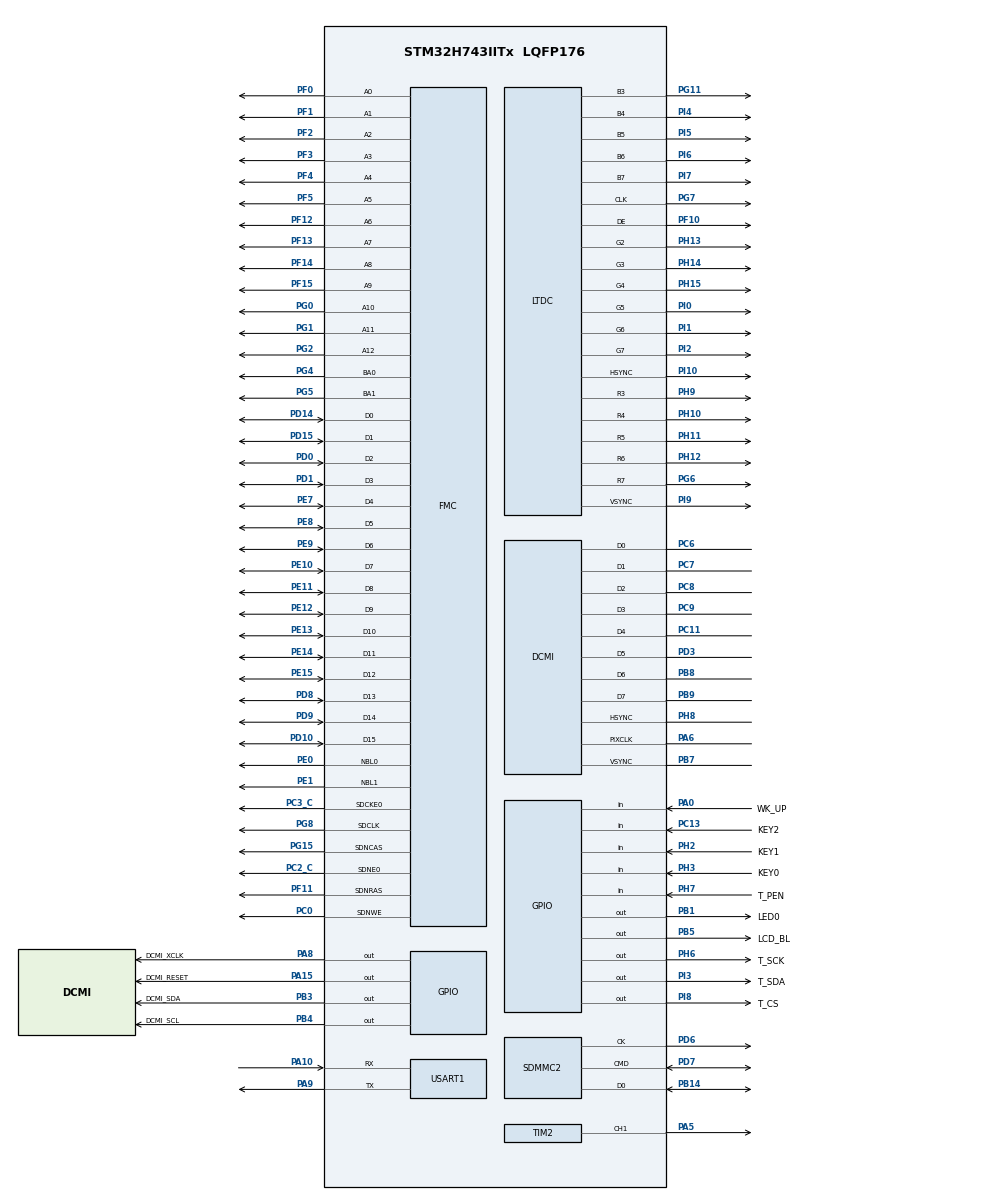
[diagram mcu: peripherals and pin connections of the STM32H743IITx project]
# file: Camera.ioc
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CORTEX_M7.AccessPermission_S-Cortex_Memory_Protection_Unit_Region1_Settings_S=MPU_REGION_FULL_ACCESS
CORTEX_M7.AccessPermission_S-Cortex_Memory_Protection_Unit_Region2_Settings_S=MPU_REGION_FULL_ACCESS
CORTEX_M7.AccessPermission_Spec=MPU_REGION_NO_ACCESS
CORTEX_M7.BaseAddress_S-Cortex_Memory_Protection_Unit_Region1_Settings_S=0xC0000000
CORTEX_M7.BaseAddress_S-Cortex_Memory_Protection_Unit_Region2_Settings_S=0x24000000
CORTEX_M7.BaseAddress_Spec=0
CORTEX_M7.CPU_DCache=Enabled
CORTEX_M7.CPU_ICache=Enabled
CORTEX_M7.DisableExec_S-Cortex_Memory_Protection_Unit_Region1_Settings_S=MPU_INSTRUCTION_ACCESS_DISABLE
CORTEX_M7.DisableExec_Spec=MPU_INSTRUCTION_ACCESS_DISABLE
CORTEX_M7.Enable_S-Cortex_Memory_Protection_Unit_Region1_Settings_S=MPU_REGION_ENABLE
CORTEX_M7.Enable_S-Cortex_Memory_Protection_Unit_Region2_Settings_S=MPU_REGION_ENABLE
CORTEX_M7.Enable_S-Cortex_Memory_Protection_Unit_Region3_Settings_S=__NULL
CORTEX_M7.Enable_Spec=MPU_REGION_ENABLE
CORTEX_M7.IsBufferable_S-Cortex_Memory_Protection_Unit_Region2_Settings_S=MPU_ACCESS_BUFFERABLE
CORTEX_M7.IsCacheable_S-Cortex_Memory_Protection_Unit_Region2_Settings_S=MPU_ACCESS_CACHEABLE
CORTEX_M7.IsShareable_Spec=MPU_ACCESS_NOT_SHAREABLE
CORTEX_M7.MPU_Control=MPU_PRIVILEGED_DEFAULT
CORTEX_M7.Size_S-Cortex_Memory_Protection_Unit_Region1_Settings_S=MPU_REGION_SIZE_32MB
CORTEX_M7.Size_S-Cortex_Memory_Protection_Unit_Region2_Settings_S=MPU_REGION_SIZE_512KB
CORTEX_M7.Size_Spec=MPU_REGION_SIZE_4GB
CORTEX_M7.TypeExtField_S-Cortex_Memory_Protection_Unit_Region1_Settings_S=MPU_TEX_LEVEL1
CORTEX_M7.TypeExtField_S-Cortex_Memory_Protection_Unit_Region2_Settings_S=MPU_TEX_LEVEL1
CORTEX_M7.default_mode_Activation=1
DCMI.HSPolarity=DCMI_HSPOLARITY_HIGH
DCMI.PCKPolarity=DCMI_PCKPOLARITY_RISING
DCMI.VSPolarity=DCMI_VSPOLARITY_HIGH
DMA2D.ColorMode=DMA2D_OUTPUT_RGB565
DMA2D.Mode=DMA2D_M2M
Dma.DCMI.0.Direction=DMA_PERIPH_TO_MEMORY
Dma.DCMI.0.EventEnable=DISABLE
Dma.DCMI.0.FIFOMode=DMA_FIFOMODE_DISABLE
Dma.DCMI.0.Instance=DMA1_Stream0
Dma.DCMI.0.MemDataAlignment=DMA_MDATAALIGN_WORD
Dma.DCMI.0.MemInc=DMA_MINC_ENABLE
Dma.DCMI.0.Mode=DMA_NORMAL
Dma.DCMI.0.PeriphDataAlignment=DMA_PDATAALIGN_WORD
Dma.DCMI.0.PeriphInc=DMA_PINC_DISABLE
Dma.DCMI.0.Polarity=HAL_DMAMUX_REQ_GEN_RISING
Dma.DCMI.0.Priority=DMA_PRIORITY_VERY_HIGH
Dma.DCMI.0.RequestNumber=1
Dma.DCMI.0.SignalID=NONE
Dma.DCMI.0.SyncEnable=DISABLE
Dma.DCMI.0.SyncPolarity=HAL_DMAMUX_SYNC_NO_EVENT
Dma.DCMI.0.SyncRequestNumber=1
Dma.DCMI.0.SyncSignalID=NONE
Dma.Request0=DCMI
FMC.CASLatency1=FMC_SDRAM_CAS_LATENCY_3
FMC.ColumnBitsNumber1=FMC_SDRAM_COLUMN_BITS_NUM_9
FMC.ExitSelfRefreshDelay1=7
FMC.LoadToActiveDelay1=2
FMC.RCDDelay1=2
FMC.RPDelay1=2
FMC.ReadBurst1=FMC_SDRAM_RBURST_ENABLE
FMC.ReadPipeDelay1=FMC_SDRAM_RPIPE_DELAY_1
FMC.RowCycleDelay1=7
FMC.SDClockPeriod1=FMC_SDRAM_CLOCK_PERIOD_2
FMC.SelfRefreshTime1=4
FMC.WriteRecoveryTime1=3
FREERTOS.MEMORY_ALLOCATION=0
FREERTOS.Tasks01=Initial_Task,1,2048,initial_task_routine,As weak,NULL,Dynamic,NULL,NULL;TouchSence_Task,0,2048,touch_sence_routine,As weak,NULL,Dynamic,NULL,NULL;Camera_Task,0,2048,camera_task_routine,As weak,NULL,Dynamic,NULL,NULL
FREERTOS.configCHECK_FOR_STACK_OVERFLOW=1
FREERTOS.configENABLE_FPU=1
FREERTOS.configGENERATE_RUN_TIME_STATS=1
FREERTOS.configLIBRARY_LOWEST_INTERRUPT_PRIORITY=15
FREERTOS.configLIBRARY_MAX_SYSCALL_INTERRUPT_PRIORITY=6
FREERTOS.configMAX_PRIORITIES=15
FREERTOS.configMINIMAL_STACK_SIZE=512
FREERTOS.configQUEUE_REGISTRY_SIZE=32
FREERTOS.configTIMER_TASK_PRIORITY=6
FREERTOS.configTIMER_TASK_STACK_DEPTH=2048
FREERTOS.configTOTAL_HEAP_SIZE=131072
FREERTOS.configUSE_COUNTING_SEMAPHORES=1
FREERTOS.configUSE_CO_ROUTINES=1
FREERTOS.configUSE_IDLE_HOOK=1
FREERTOS.configUSE_MALLOC_FAILED_HOOK=1
FREERTOS.configUSE_NEWLIB_REENTRANT=1
FREERTOS.configUSE_RECURSIVE_MUTEXES=1
FREERTOS.configUSE_STATS_FORMATTING_FUNCTIONS=1
FREERTOS.configUSE_TICK_HOOK=1
FREERTOS.configUSE_TIMERS=1
FREERTOS.configUSE_TRACE_FACILITY=1
JPEG.JPEG_RGB_FORMAT=JPEG_RGB565
JPEG.JPEG_SWAP_RG=1
LTDC.ActiveH=272
LTDC.ActiveW=480
LTDC.Alpha0_L0=0
LTDC.Alpha_L0=255
LTDC.Alpha_L1=255
LTDC.BlendingFactor1_L0=LTDC_BLENDING_FACTOR1_CA
LTDC.BlendingFactor1_L1=LTDC_BLENDING_FACTOR1_PAxCA
LTDC.BlendingFactor2_L0=LTDC_BLENDING_FACTOR2_CA
LTDC.BlendingFactor2_L1=LTDC_BLENDING_FACTOR2_PAxCA
LTDC.Blue=255
LTDC.Blue_L0=0
LTDC.FBStartAdress_L0=0
LTDC.FBStartAdress_L1=SDRAM_LAYER1
LTDC.Green=255
LTDC.Green_L0=0
LTDC.HBP=40
LTDC.HFP=5
LTDC.HSync=1
LTDC.ImageHeight_L0=272
LTDC.ImageHeight_L1=272
LTDC.ImageWidth_L0=480
LTDC.Layers=0
LTDC.PCPolarity=LTDC_PCPOLARITY_IPC
LTDC.PixelFormat_L0=LTDC_PIXEL_FORMAT_RGB565
LTDC.Red=255
LTDC.Red_L0=0
LTDC.VBP=8
LTDC.VFP=8
LTDC.VSync=1
LTDC.WindowX1_L0=480
LTDC.WindowX1_L1=480
LTDC.WindowY1_L0=272
LTDC.WindowY1_L1=272
Mcu.Family=STM32H7
Mcu.Name=STM32H743IITx
Mcu.Package=LQFP176
Mdma.MDMA_Channel0.JPEG_INFIFO_TH.0.BlockCount=0
Mdma.MDMA_Channel0.JPEG_INFIFO_TH.0.BlockDataLength=0
Mdma.MDMA_Channel0.JPEG_INFIFO_TH.0.BufferTransferLength=32
Mdma.MDMA_Channel0.JPEG_INFIFO_TH.0.CircularMode=MDMA_LINEAR_LIST
Mdma.MDMA_Channel0.JPEG_INFIFO_TH.0.DataAlignment=MDMA_DATAALIGN_PACKENABLE
Mdma.MDMA_Channel0.JPEG_INFIFO_TH.0.DestBlockAddressOffset=0
Mdma.MDMA_Channel0.JPEG_INFIFO_TH.0.DestBurst=MDMA_DEST_BURST_16BEATS
Mdma.MDMA_Channel0.JPEG_INFIFO_TH.0.DestDataSize=MDMA_DEST_DATASIZE_WORD
Mdma.MDMA_Channel0.JPEG_INFIFO_TH.0.DestinationInc=MDMA_DEST_INC_DISABLE
Mdma.MDMA_Channel0.JPEG_INFIFO_TH.0.DstAddress=0
Mdma.MDMA_Channel0.JPEG_INFIFO_TH.0.Endianness=MDMA_LITTLE_ENDIANNESS_PRESERVE
Mdma.MDMA_Channel0.JPEG_INFIFO_TH.0.Instance=MDMA_Channel0
Mdma.MDMA_Channel0.JPEG_INFIFO_TH.0.MaskAddress=0
Mdma.MDMA_Channel0.JPEG_INFIFO_TH.0.MaskData=0
Mdma.MDMA_Channel0.JPEG_INFIFO_TH.0.Priority=MDMA_PRIORITY_LOW
Mdma.MDMA_Channel0.JPEG_INFIFO_TH.0.Rank=First
Mdma.MDMA_Channel0.JPEG_INFIFO_TH.0.SourceBlockAddressOffset=0
Mdma.MDMA_Channel0.JPEG_INFIFO_TH.0.SourceBurst=MDMA_SOURCE_BURST_32BEATS
Mdma.MDMA_Channel0.JPEG_INFIFO_TH.0.SourceDataSize=MDMA_SRC_DATASIZE_BYTE
Mdma.MDMA_Channel0.JPEG_INFIFO_TH.0.SourceInc=MDMA_SRC_INC_BYTE
Mdma.MDMA_Channel0.JPEG_INFIFO_TH.0.SrcAddress=0
Mdma.MDMA_Channel0.JPEG_INFIFO_TH.0.TransferTriggerMode=MDMA_BUFFER_TRANSFER
Mdma.MDMA_Channel0.Request0=JPEG_INFIFO_TH
Mdma.MDMA_Channel0.RequestsNb=1
Mdma.MDMA_Channel1.JPEG_OUTFIFO_TH.0.BlockCount=0
Mdma.MDMA_Channel1.JPEG_OUTFIFO_TH.0.BlockDataLength=0
Mdma.MDMA_Channel1.JPEG_OUTFIFO_TH.0.BufferTransferLength=32
Mdma.MDMA_Channel1.JPEG_OUTFIFO_TH.0.CircularMode=MDMA_LINEAR_LIST
Mdma.MDMA_Channel1.JPEG_OUTFIFO_TH.0.DataAlignment=MDMA_DATAALIGN_PACKENABLE
Mdma.MDMA_Channel1.JPEG_OUTFIFO_TH.0.DestBlockAddressOffset=0
Mdma.MDMA_Channel1.JPEG_OUTFIFO_TH.0.DestBurst=MDMA_DEST_BURST_32BEATS
Mdma.MDMA_Channel1.JPEG_OUTFIFO_TH.0.DestDataSize=MDMA_DEST_DATASIZE_BYTE
Mdma.MDMA_Channel1.JPEG_OUTFIFO_TH.0.DestinationInc=MDMA_DEST_INC_BYTE
Mdma.MDMA_Channel1.JPEG_OUTFIFO_TH.0.DstAddress=0
Mdma.MDMA_Channel1.JPEG_OUTFIFO_TH.0.Endianness=MDMA_LITTLE_ENDIANNESS_PRESERVE
Mdma.MDMA_Channel1.JPEG_OUTFIFO_TH.0.Instance=MDMA_Channel1
Mdma.MDMA_Channel1.JPEG_OUTFIFO_TH.0.MaskAddress=0
Mdma.MDMA_Channel1.JPEG_OUTFIFO_TH.0.MaskData=0
Mdma.MDMA_Channel1.JPEG_OUTFIFO_TH.0.Priority=MDMA_PRIORITY_LOW
Mdma.MDMA_Channel1.JPEG_OUTFIFO_TH.0.Rank=First
Mdma.MDMA_Channel1.JPEG_OUTFIFO_TH.0.SourceBlockAddressOffset=0
Mdma.MDMA_Channel1.JPEG_OUTFIFO_TH.0.SourceBurst=MDMA_SOURCE_BURST_16BEATS
Mdma.MDMA_Channel1.JPEG_OUTFIFO_TH.0.SourceDataSize=MDMA_SRC_DATASIZE_WORD
Mdma.MDMA_Channel1.JPEG_OUTFIFO_TH.0.SourceInc=MDMA_SRC_INC_DISABLE
Mdma.MDMA_Channel1.JPEG_OUTFIFO_TH.0.SrcAddress=0
Mdma.MDMA_Channel1.JPEG_OUTFIFO_TH.0.TransferTriggerMode=MDMA_BUFFER_TRANSFER
Mdma.MDMA_Channel1.Request0=JPEG_OUTFIFO_TH
Mdma.MDMA_Channel1.RequestsNb=1
Mdma.RequestSet0=MDMA_Channel0
Mdma.RequestSet1=MDMA_Channel1
Mdma.RequestSetsNb=2
NVIC.DMA1_Stream0_IRQn=true\:6\:0\:false\:false\:true\:true\:false\:true\:true
NVIC.DMA2D_IRQn=true\:6\:0\:false\:false\:true\:true\:true\:true\:true
NVIC.FMC_IRQn=true\:6\:0\:false\:false\:true\:true\:true\:true\:true
NVIC.JPEG_IRQn=true\:6\:0\:false\:false\:true\:true\:true\:true\:true
NVIC.LTDC_IRQn=true\:6\:0\:false\:false\:true\:true\:true\:true\:true
NVIC.MDMA_IRQn=true\:6\:0\:false\:false\:true\:true\:false\:true\:true
NVIC.PriorityGroup=NVIC_PRIORITYGROUP_4
NVIC.TIM3_IRQn=true\:5\:0\:true\:false\:true\:false\:true\:true\:true
NVIC.TIM7_IRQn=true\:15\:0\:true\:false\:true\:false\:false\:true\:true
NVIC.TimeBase=TIM7_IRQn
NVIC.TimeBaseIP=TIM7
PA0.GPIO_Label=WK_UP
PA0.GPIO_PuPd=GPIO_PULLDOWN
PA0.Signal=GPIO_Input
PA10.GPIO_Speed=GPIO_SPEED_FREQ_VERY_HIGH
PA10.Mode=Asynchronous
PA10.Signal=USART1_RX
PA13\ (JTMS/SWDIO).Mode=Serial_Wire
PA13\ (JTMS/SWDIO).Signal=DEBUG_JTMS-SWDIO
PA14\ (JTCK/SWCLK).Mode=Serial_Wire
PA14\ (JTCK/SWCLK).Signal=DEBUG_JTCK-SWCLK
PA15\ (JTDI).GPIO_Label=DCMI_RESET
PA15\ (JTDI).GPIO_Speed=GPIO_SPEED_FREQ_VERY_HIGH
PA15\ (JTDI).Signal=GPIO_Output
PA5.GPIO_Speed=GPIO_SPEED_FREQ_VERY_HIGH
PA5.Signal=S_TIM2_CH1_ETR
PA6.GPIO_Speed=GPIO_SPEED_FREQ_VERY_HIGH
PA6.Mode=Slave_8_bits_External_Synchro
PA6.Signal=DCMI_PIXCLK
PA8.GPIO_Label=DCMI_XCLK
PA8.GPIO_Speed=GPIO_SPEED_FREQ_VERY_HIGH
PA8.Signal=GPIO_Output
PA9.GPIO_Speed=GPIO_SPEED_FREQ_VERY_HIGH
PA9.Mode=Asynchronous
PA9.Signal=USART1_TX
PB1.GPIO_Label=LED0
PB1.GPIO_Speed=GPIO_SPEED_FREQ_VERY_HIGH
PB1.PinState=GPIO_PIN_SET
PB1.Signal=GPIO_Output
PB14.Mode=SD_1_bit
PB14.Signal=SDMMC2_D0
PB3\ (JTDO/TRACESWO).GPIO_Label=DCMI_SDA
PB3\ (JTDO/TRACESWO).GPIO_Speed=GPIO_SPEED_FREQ_VERY_HIGH
PB3\ (JTDO/TRACESWO).PinState=GPIO_PIN_RESET
PB3\ (JTDO/TRACESWO).Signal=GPIO_Output
PB4\ (NJTRST).GPIO_Label=DCMI_SCL
PB4\ (NJTRST).GPIO_Speed=GPIO_SPEED_FREQ_VERY_HIGH
PB4\ (NJTRST).Signal=GPIO_Output
PB5.GPIO_Label=LCD_BL
PB5.GPIO_Speed=GPIO_SPEED_FREQ_VERY_HIGH
PB5.PinState=GPIO_PIN_SET
PB5.Signal=GPIO_Output
PB7.GPIO_Speed=GPIO_SPEED_FREQ_VERY_HIGH
PB7.Mode=Slave_8_bits_External_Synchro
PB7.Signal=DCMI_VSYNC
PB8.GPIO_Speed=GPIO_SPEED_FREQ_VERY_HIGH
PB8.Mode=Slave_8_bits_External_Synchro
PB8.Signal=DCMI_D6
PB9.GPIO_Speed=GPIO_SPEED_FREQ_VERY_HIGH
PB9.Mode=Slave_8_bits_External_Synchro
PB9.Signal=DCMI_D7
PC0.Signal=FMC_SDNWE
PC10.Signal=SDMMC1_D2
PC11.Signal=SharedStack_PC11
PC11.Stacked=true
PC12.Signal=SDMMC1_CK
PC13.GPIO_Label=KEY2
PC13.GPIO_Mode=GPIO_MODE_INPUT
PC13.GPIO_PuPd=GPIO_PULLUP
PC13.Signal=GPIO_Input
PC14-OSC32_IN\ (OSC32_IN).Mode=LSE-External-Oscillator
PC14-OSC32_IN\ (OSC32_IN).Signal=RCC_OSC32_IN
PC15-OSC32_OUT\ (OSC32_OUT).Mode=LSE-External-Oscillator
PC15-OSC32_OUT\ (OSC32_OUT).Signal=RCC_OSC32_OUT
PC2_C.Mode=SdramChipSelect1_1
PC2_C.Signal=FMC_SDNE0
PC3_C.Mode=SdramChipSelect1_1
PC3_C.Signal=FMC_SDCKE0
PC6.GPIO_Speed=GPIO_SPEED_FREQ_VERY_HIGH
PC6.Mode=Slave_8_bits_External_Synchro
PC6.Signal=DCMI_D0
PC7.GPIO_Speed=GPIO_SPEED_FREQ_VERY_HIGH
PC7.Mode=Slave_8_bits_External_Synchro
PC7.Signal=DCMI_D1
PC8.Mode=Slave_8_bits_External_Synchro
PC8.Signal=DCMI_D2
PC8.Stacked=true
PC9.Mode=Slave_8_bits_External_Synchro
PC9.Signal=DCMI_D3
PC9.Stacked=true
PD0.Signal=FMC_D2_DA2
PD1.Signal=FMC_D3_DA3
PD10.Signal=FMC_D15_DA15
PD14.Signal=FMC_D0_DA0
PD15.Signal=FMC_D1_DA1
PD2.Signal=SDMMC1_CMD
PD3.GPIO_Speed=GPIO_SPEED_FREQ_VERY_HIGH
PD3.Mode=Slave_8_bits_External_Synchro
PD3.Signal=DCMI_D5
PD6.Mode=SD_1_bit
PD6.Signal=SDMMC2_CK
PD7.Mode=SD_1_bit
PD7.Signal=SDMMC2_CMD
PD8.Signal=FMC_D13_DA13
PD9.Signal=FMC_D14_DA14
PE0.Signal=FMC_NBL0
PE1.Signal=FMC_NBL1
PE10.Signal=FMC_D7_DA7
PE11.Signal=FMC_D8_DA8
PE12.Signal=FMC_D9_DA9
PE13.Signal=FMC_D10_DA10
PE14.Signal=FMC_D11_DA11
PE15.Signal=FMC_D12_DA12
PE7.Signal=FMC_D4_DA4
PE8.Signal=FMC_D5_DA5
PE9.Signal=FMC_D6_DA6
PF0.Signal=FMC_A0
PF1.Signal=FMC_A1
PF10.GPIO_Speed=GPIO_SPEED_FREQ_VERY_HIGH
PF10.Mode=RGB565
PF10.Signal=LTDC_DE
PF11.Signal=FMC_SDNRAS
PF12.Signal=FMC_A6
PF13.Signal=FMC_A7
PF14.Signal=FMC_A8
PF15.Signal=FMC_A9
PF2.Signal=FMC_A2
PF3.Signal=FMC_A3
PF4.Signal=FMC_A4
PF5.Signal=FMC_A5
PG0.Signal=FMC_A10
PG1.Signal=FMC_A11
PG11.GPIO_Speed=GPIO_SPEED_FREQ_VERY_HIGH
PG11.Mode=RGB565
PG11.Signal=LTDC_B3
PG15.Signal=FMC_SDNCAS
PG2.Signal=FMC_A12
PG4.Signal=FMC_A14_BA0
PG5.Signal=FMC_A15_BA1
PG6.GPIO_Speed=GPIO_SPEED_FREQ_VERY_HIGH
PG6.Mode=RGB565
PG6.Signal=LTDC_R7
PG7.GPIO_Speed=GPIO_SPEED_FREQ_VERY_HIGH
PG7.Mode=RGB565
PG7.Signal=LTDC_CLK
PG8.Signal=FMC_SDCLK
PH0-OSC_IN\ (PH0).Mode=HSE-External-Oscillator
PH0-OSC_IN\ (PH0).Signal=RCC_OSC_IN
PH1-OSC_OUT\ (PH1).Mode=HSE-External-Oscillator
PH1-OSC_OUT\ (PH1).Signal=RCC_OSC_OUT
PH10.GPIO_Speed=GPIO_SPEED_FREQ_VERY_HIGH
PH10.Mode=RGB565
PH10.Signal=LTDC_R4
PH11.GPIO_Speed=GPIO_SPEED_FREQ_VERY_HIGH
PH11.Mode=RGB565
PH11.Signal=LTDC_R5
PH12.GPIO_Speed=GPIO_SPEED_FREQ_VERY_HIGH
PH12.Mode=RGB565
PH12.Signal=LTDC_R6
PH13.GPIO_Speed=GPIO_SPEED_FREQ_VERY_HIGH
PH13.Mode=RGB565
PH13.Signal=LTDC_G2
PH14.GPIO_Speed=GPIO_SPEED_FREQ_VERY_HIGH
PH14.Mode=RGB565
PH14.Signal=LTDC_G3
PH15.GPIO_Speed=GPIO_SPEED_FREQ_VERY_HIGH
PH15.Mode=RGB565
PH15.Signal=LTDC_G4
PH2.GPIO_Label=KEY1
PH2.GPIO_Mode=GPIO_MODE_INPUT
PH2.GPIO_PuPd=GPIO_PULLUP
PH2.Signal=GPIO_Input
PH3.GPIO_Label=KEY0
PH3.GPIO_Mode=GPIO_MODE_INPUT
PH3.GPIO_PuPd=GPIO_PULLUP
PH3.Signal=GPIO_Input
PH6.GPIO_Label=T_SCK
PH6.GPIO_ModeDefaultOutputPP=GPIO_MODE_OUTPUT_OD
PH6.GPIO_PuPd=GPIO_PULLUP
PH6.GPIO_Speed=GPIO_SPEED_FREQ_VERY_HIGH
PH6.PinState=GPIO_PIN_SET
PH6.Signal=GPIO_Output
PH7.GPIO_Label=T_PEN
PH7.GPIO_PuPd=GPIO_PULLUP
PH7.Signal=GPIO_Input
PH8.GPIO_Speed=GPIO_SPEED_FREQ_VERY_HIGH
PH8.Mode=Slave_8_bits_External_Synchro
PH8.Signal=DCMI_HSYNC
PH9.GPIO_Speed=GPIO_SPEED_FREQ_VERY_HIGH
PH9.Mode=RGB565
PH9.Signal=LTDC_R3
PI0.GPIO_Speed=GPIO_SPEED_FREQ_VERY_HIGH
PI0.Mode=RGB565
PI0.Signal=LTDC_G5
PI1.GPIO_Speed=GPIO_SPEED_FREQ_VERY_HIGH
PI1.Mode=RGB565
PI1.Signal=LTDC_G6
PI10.GPIO_Speed=GPIO_SPEED_FREQ_VERY_HIGH
PI10.Mode=RGB565
PI10.Signal=LTDC_HSYNC
PI2.GPIO_Speed=GPIO_SPEED_FREQ_VERY_HIGH
PI2.Mode=RGB565
PI2.Signal=LTDC_G7
PI3.GPIO_Label=T_SDA
PI3.GPIO_ModeDefaultOutputPP=GPIO_MODE_OUTPUT_OD
PI3.GPIO_PuPd=GPIO_PULLUP
PI3.GPIO_Speed=GPIO_SPEED_FREQ_VERY_HIGH
PI3.PinState=GPIO_PIN_SET
PI3.Signal=GPIO_Output
PI4.GPIO_Speed=GPIO_SPEED_FREQ_VERY_HIGH
PI4.Mode=RGB565
PI4.Signal=LTDC_B4
PI5.GPIO_Speed=GPIO_SPEED_FREQ_VERY_HIGH
PI5.Mode=RGB565
PI5.Signal=LTDC_B5
PI6.GPIO_Speed=GPIO_SPEED_FREQ_VERY_HIGH
PI6.Mode=RGB565
PI6.Signal=LTDC_B6
PI7.GPIO_Speed=GPIO_SPEED_FREQ_VERY_HIGH
PI7.Mode=RGB565
PI7.Signal=LTDC_B7
PI8.GPIO_Label=T_CS
PI8.GPIO_PuPd=GPIO_NOPULL
PI8.GPIO_Speed=GPIO_SPEED_FREQ_LOW
PI8.PinState=GPIO_PIN_RESET
PI8.Signal=GPIO_Output
PI9.GPIO_Speed=GPIO_SPEED_FREQ_VERY_HIGH
PI9.Mode=RGB565
PI9.Signal=LTDC_VSYNC
ProjectManager.HeapSize=0x1000
ProjectManager.StackSize=0x1000
ProjectManager.TargetToolchain=CMake
RCC.ADCFreq_Value=100000000
RCC.APB1Freq_Value=120000000
RCC.APB2Freq_Value=120000000
RCC.APB3Freq_Value=120000000
RCC.APB4Freq_Value=120000000
RCC.CortexFreq_Value=480000000
RCC.D1PPRE=RCC_APB3_DIV2
RCC.D2PPRE1=RCC_APB1_DIV2
RCC.D2PPRE2=RCC_APB2_DIV2
RCC.D3PPRE=RCC_APB4_DIV2
RCC.DIVM1=5
RCC.DIVM2=5
RCC.DIVM3=5
RCC.DIVN1=192
RCC.DIVN2=40
RCC.DIVN3=36
RCC.DIVQ1=3
RCC.DIVR2=1
RCC.DIVR3=20
RCC.FMCCLockSelection=RCC_FMCCLKSOURCE_PLL2
RCC.HCLKFreq_Value=240000000
RCC.HPRE=RCC_HCLK_DIV2
RCC.PLL2FRACN=0
RCC.PLLSourceVirtual=RCC_PLLSOURCE_HSE
RCC.RTCClockSelection=RCC_RTCCLKSOURCE_LSE
RCC.SDMMC1CLockSelection=RCC_SDMMCCLKSOURCE_PLL2
RCC.SYSCLKFreq_VALUE=480000000
RCC.SYSCLKSource=RCC_SYSCLKSOURCE_PLLCLK
RCC.Tim1Mul=2
RCC.USBFreq_Value=320000000
RTC.Date=8
RTC.Hours=0
RTC.Minutes=0
RTC.Month=RTC_MONTH_NOVEMBER
RTC.Seconds=0
RTC.WeekDay=RTC_WEEKDAY_SATURDAY
RTC.Year=23
SDMMC2.ClockDiv=4
SH.FMC_A0.0=FMC_A0,13b-sda1
SH.FMC_A1.0=FMC_A1,13b-sda1
SH.FMC_A10.0=FMC_A10,13b-sda1
SH.FMC_A11.0=FMC_A11,13b-sda1
SH.FMC_A12.0=FMC_A12,13b-sda1
SH.FMC_A14_BA0.0=FMC_BA0,FourSdramBanks1
SH.FMC_A15_BA1.0=FMC_BA1,FourSdramBanks1
SH.FMC_A2.0=FMC_A2,13b-sda1
SH.FMC_A3.0=FMC_A3,13b-sda1
SH.FMC_A4.0=FMC_A4,13b-sda1
SH.FMC_A5.0=FMC_A5,13b-sda1
SH.FMC_A6.0=FMC_A6,13b-sda1
SH.FMC_A7.0=FMC_A7,13b-sda1
SH.FMC_A8.0=FMC_A8,13b-sda1
SH.FMC_A9.0=FMC_A9,13b-sda1
SH.FMC_D0_DA0.0=FMC_D0,sd-16b-d1
SH.FMC_D10_DA10.0=FMC_D10,sd-16b-d1
SH.FMC_D11_DA11.0=FMC_D11,sd-16b-d1
SH.FMC_D12_DA12.0=FMC_D12,sd-16b-d1
SH.FMC_D13_DA13.0=FMC_D13,sd-16b-d1
SH.FMC_D14_DA14.0=FMC_D14,sd-16b-d1
SH.FMC_D15_DA15.0=FMC_D15,sd-16b-d1
SH.FMC_D1_DA1.0=FMC_D1,sd-16b-d1
SH.FMC_D2_DA2.0=FMC_D2,sd-16b-d1
SH.FMC_D3_DA3.0=FMC_D3,sd-16b-d1
SH.FMC_D4_DA4.0=FMC_D4,sd-16b-d1
SH.FMC_D5_DA5.0=FMC_D5,sd-16b-d1
SH.FMC_D6_DA6.0=FMC_D6,sd-16b-d1
SH.FMC_D7_DA7.0=FMC_D7,sd-16b-d1
SH.FMC_D8_DA8.0=FMC_D8,sd-16b-d1
SH.FMC_D9_DA9.0=FMC_D9,sd-16b-d1
SH.FMC_NBL0.0=FMC_NBL0,Sd2ByteEnable1
SH.FMC_NBL1.0=FMC_NBL1,Sd2ByteEnable1
SH.FMC_SDCLK.0=FMC_SDCLK,13b-sda1
SH.FMC_SDNCAS.0=FMC_SDNCAS,13b-sda1
SH.FMC_SDNRAS.0=FMC_SDNRAS,13b-sda1
SH.FMC_SDNWE.0=FMC_SDNWE,13b-sda1
SH.S_TIM2_CH1_ETR.0=TIM2_CH1,PWM Generation1 CH1
SH.SharedStack_PC11.0=DCMI_D4,Slave_8_bits_External_Synchro
SH.SharedStack_PC11.1=SDMMC1_D3
STMicroelectronics.X-CUBE-TOUCHGFX.4.24.0_IsPackSelfContextualization=true
TIM2.Channel-PWM\ Generation1\ CH1=TIM_CHANNEL_1
TIM2.Period=1000-1
TIM2.Prescaler=240-1
TIM2.Pulse-PWM\ Generation1\ CH1=600
TIM3.Period=499
TIM3.Prescaler=239
TIM6.AutoReloadPreload=TIM_AUTORELOAD_PRELOAD_ENABLE
TIM6.Period=0
TIM6.Prescaler=120-1
USART1.VirtualMode-Asynchronous=VM_ASYNC
VP_DMA2D_VS_DMA2D.Mode=DMA2D_Activate
VP_FREERTOS_VS_CMSIS_V1.Mode=CMSIS_V1
VP_JPEG_VS_JPEG.Mode=JPEG_Activate
VP_LIBJPEG_VS_JPEGLIB.Mode=Enabled
VP_MEMORYMAP_VS_MEMORYMAP.Mode=CurAppReg
VP_RTC_VS_RTC_Activate.Mode=RTC_Enabled
VP_RTC_VS_RTC_Calendar.Mode=RTC_Calendar
VP_SYS_VS_tim7.Mode=TIM7
VP_TIM12_VS_ClockSourceINT.Mode=Internal
VP_TIM2_VS_ClockSourceINT.Mode=Internal
VP_TIM3_VS_ClockSourceINT.Mode=Internal
VP_TIM6_VS_ClockSourceINT.Mode=Enable_Timer
board=custom

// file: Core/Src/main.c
/* USER CODE BEGIN Header */
/**
 ******************************************************************************
 * @file           : main.c
 * @brief          : Main program body
 ******************************************************************************
 * @attention
 *
 * Copyright (c) 2025 STMicroelectronics.
 * All rights reserved.
 *
 * This software is licensed under terms that can be found in the LICENSE file
 * in the root directory of this software component.
 * If no LICENSE file comes with this software, it is provided AS-IS.
 *
 ******************************************************************************
 */
/* USER CODE END Header */
#include "main.h"
#include "cmsis_os.h"
#include "dcmi.h"
#include "dma.h"
#include "dma2d.h"
#include "fatfs.h"
#include "jpeg.h"
#include "libjpeg.h"
#include "ltdc.h"
#include "mdma.h"
#include "memorymap.h"
#include "rtc.h"
#include "sdmmc.h"
#include "tim.h"
#include "usart.h"
#include "dma.h"
#include "gpio.h"
#include "fmc.h"

/* USER CODE BEGIN Includes */
#include <string.h>
/* USER CODE END Includes */

/* USER CODE BEGIN PV */
void *const sram2_end_ptr   = &sram2_end;
void *const sram3_end_ptr   = &sram3_end;
void *const sdram_start_ptr = &sdram_start;
void *const sdram_end_ptr   = &sdram_end;
/* USER CODE END PV */

void        SystemClock_Config(void);
void        PeriphCommonClock_Config(void);
static void MPU_Config(void);
void        MX_FREERTOS_Init(void);

/* USER CODE BEGIN 0 */
extern uint8_t fatfs_align;
/* USER CODE END 0 */

int main(void) {

    /* MPU Configuration--------------------------------------------------------*/
    MPU_Config();

    /* Enable the CPU Cache */
#if USE_CACHE_ID == 1
    /* Enable I-Cache---------------------------------------------------------*/
    SCB_EnableICache();

    /* Enable D-Cache---------------------------------------------------------*/
    SCB_EnableDCache();
#endif

    /* MCU Configuration--------------------------------------------------------*/

    /* Reset of all peripherals, Initializes the Flash interface and the Systick. */
    HAL_Init();

    /* Configure the system clock */
    SystemClock_Config();

    /* Configure the peripherals common clocks */
    PeriphCommonClock_Config();

    /* USER CODE BEGIN SysInit */
    __HAL_RCC_D2SRAM1_CLK_ENABLE();
    __HAL_RCC_D2SRAM2_CLK_ENABLE();
    __HAL_RCC_D2SRAM3_CLK_ENABLE();
    /* USER CODE END SysInit */

  /* Initialize all configured peripherals */
    MX_GPIO_Init();
    MX_MDMA_Init();
    MX_DMA_Init();
    MX_USART1_UART_Init();
    MX_TIM2_Init();
    MX_FMC_Init();
    MX_LTDC_Init();
    MX_DMA2D_Init();
    MX_JPEG_Init();
    MX_SDMMC2_SD_Init();
    MX_FATFS_Init();
    MX_TIM6_Init();
    MX_TIM3_Init();
    MX_TIM12_Init();
    MX_RTC_Init();
    MX_LIBJPEG_Init();
  /* USER CODE BEGIN 2 */
    sdcard_link_driver = 1;
    SEGGER_RTT_Init();
    GPIO_InitTypeDef GPIO_InitStruct = {0};
    GPIO_InitStruct.Pin              = T_CS_Pin;
    GPIO_InitStruct.Mode             = GPIO_MODE_OUTPUT_PP;
    GPIO_InitStruct.Pull             = GPIO_NOPULL;
    GPIO_InitStruct.Speed            = GPIO_SPEED_FREQ_VERY_HIGH;
    HAL_GPIO_Init(T_CS_GPIO_Port, &GPIO_InitStruct);
    //   MX_DCMI_Init(); This is confilt with MX_SDMMC1_SD_Init();
    //   vTraceEnable(TRC_START_FROM_HOST);
    /* USER CODE END 2 */

    /* Call init function for freertos objects (in cmsis_os2.c) */
    MX_FREERTOS_Init();

    /* Start scheduler */
    osKernelStart();

    /* We should never get here as control is now taken by the scheduler */

    /* Infinite loop */
    while (1) {

    }
}

void SystemClock_Config(void) {
    RCC_OscInitTypeDef RCC_OscInitStruct = {0};
    RCC_ClkInitTypeDef RCC_ClkInitStruct = {0};

    /** Supply configuration update enable
     */
    HAL_PWREx_ConfigSupply(PWR_LDO_SUPPLY);

    /** Configure the main internal regulator output voltage
     */
    __HAL_PWR_VOLTAGESCALING_CONFIG(PWR_REGULATOR_VOLTAGE_SCALE1);

    while (!__HAL_PWR_GET_FLAG(PWR_FLAG_VOSRDY)) {
    }

    __HAL_RCC_SYSCFG_CLK_ENABLE();
    __HAL_PWR_VOLTAGESCALING_CONFIG(PWR_REGULATOR_VOLTAGE_SCALE0);

    while (!__HAL_PWR_GET_FLAG(PWR_FLAG_VOSRDY)) {
    }

    /** Configure LSE Drive Capability
     */
    HAL_PWR_EnableBkUpAccess();
    __HAL_RCC_LSEDRIVE_CONFIG(RCC_LSEDRIVE_LOW);

    /** Initializes the RCC Oscillators according to the specified parameters
     * in the RCC_OscInitTypeDef structure.
     */
    RCC_OscInitStruct.OscillatorType = RCC_OSCILLATORTYPE_HSE | RCC_OSCILLATORTYPE_LSE;
    RCC_OscInitStruct.HSEState       = RCC_HSE_ON;
    RCC_OscInitStruct.LSEState       = RCC_LSE_ON;
    RCC_OscInitStruct.PLL.PLLState   = RCC_PLL_ON;
    RCC_OscInitStruct.PLL.PLLSource  = RCC_PLLSOURCE_HSE;
    RCC_OscInitStruct.PLL.PLLM       = 5;
    RCC_OscInitStruct.PLL.PLLN       = 192;
    RCC_OscInitStruct.PLL.PLLP       = 2;
    RCC_OscInitStruct.PLL.PLLQ       = 3;
    RCC_OscInitStruct.PLL.PLLR       = 2;
    RCC_OscInitStruct.PLL.PLLRGE     = RCC_PLL1VCIRANGE_2;
    RCC_OscInitStruct.PLL.PLLVCOSEL  = RCC_PLL1VCOWIDE;
    RCC_OscInitStruct.PLL.PLLFRACN   = 0;
    if (HAL_RCC_OscConfig(&RCC_OscInitStruct) != HAL_OK) {
        Error_Handler();
    }

    /** Initializes the CPU, AHB and APB buses clocks
     */
    RCC_ClkInitStruct.ClockType      = RCC_CLOCKTYPE_HCLK | RCC_CLOCKTYPE_SYSCLK | RCC_CLOCKTYPE_PCLK1 | RCC_CLOCKTYPE_PCLK2 | RCC_CLOCKTYPE_D3PCLK1 | RCC_CLOCKTYPE_D1PCLK1;
    RCC_ClkInitStruct.SYSCLKSource   = RCC_SYSCLKSOURCE_PLLCLK;
    RCC_ClkInitStruct.SYSCLKDivider  = RCC_SYSCLK_DIV1;
    RCC_ClkInitStruct.AHBCLKDivider  = RCC_HCLK_DIV2;
    RCC_ClkInitStruct.APB3CLKDivider = RCC_APB3_DIV2;
    RCC_ClkInitStruct.APB1CLKDivider = RCC_APB1_DIV2;
    RCC_ClkInitStruct.APB2CLKDivider = RCC_APB2_DIV2;
    RCC_ClkInitStruct.APB4CLKDivider = RCC_APB4_DIV2;

    if (HAL_RCC_ClockConfig(&RCC_ClkInitStruct, FLASH_LATENCY_4) != HAL_OK) {
        Error_Handler();
    }
}

void PeriphCommonClock_Config(void) {
    RCC_PeriphCLKInitTypeDef PeriphClkInitStruct = {0};

    /** Initializes the peripherals clock
     */
    PeriphClkInitStruct.PeriphClockSelection = RCC_PERIPHCLK_FMC | RCC_PERIPHCLK_SDMMC;
    PeriphClkInitStruct.PLL2.PLL2M           = 5;
    PeriphClkInitStruct.PLL2.PLL2N           = 40;
    PeriphClkInitStruct.PLL2.PLL2P           = 2;
    PeriphClkInitStruct.PLL2.PLL2Q           = 2;
    PeriphClkInitStruct.PLL2.PLL2R           = 1;
    PeriphClkInitStruct.PLL2.PLL2RGE         = RCC_PLL2VCIRANGE_2;
    PeriphClkInitStruct.PLL2.PLL2VCOSEL      = RCC_PLL2VCOWIDE;
    PeriphClkInitStruct.PLL2.PLL2FRACN       = 0;
    PeriphClkInitStruct.FmcClockSelection    = RCC_FMCCLKSOURCE_PLL2;
    PeriphClkInitStruct.SdmmcClockSelection  = RCC_SDMMCCLKSOURCE_PLL2;
    if (HAL_RCCEx_PeriphCLKConfig(&PeriphClkInitStruct) != HAL_OK) {
        Error_Handler();
    }
}

/* USER CODE BEGIN 4 */
int __io_putchar(int ch) {
    uint8_t c = ch;
    HAL_UART_Transmit(&huart1, &c, 1, 0xffffffff);
    return 0;
}
int __io_getchar(void) {
    uint8_t c = 0;
    HAL_UART_Receive(&huart1, &c, 1, 0xffffffff);
    return c;
}
/* USER CODE END 4 */

/* MPU Configuration */

void MPU_Config(void) {
    MPU_Region_InitTypeDef MPU_InitStruct = {0};

    /* Disables the MPU */
    HAL_MPU_Disable();

    /** Initializes and configures the Region and the memory to be protected
     */
    MPU_InitStruct.Enable           = MPU_REGION_ENABLE;
    MPU_InitStruct.Number           = MPU_REGION_NUMBER0;
    MPU_InitStruct.BaseAddress      = 0;
    MPU_InitStruct.Size             = MPU_REGION_SIZE_4GB;
    MPU_InitStruct.SubRegionDisable = 0x87;
    MPU_InitStruct.AccessPermission = MPU_REGION_NO_ACCESS;
    MPU_InitStruct.DisableExec      = MPU_INSTRUCTION_ACCESS_DISABLE;
    MPU_InitStruct.TypeExtField     = MPU_TEX_LEVEL0;
    MPU_InitStruct.IsCacheable      = MPU_ACCESS_NOT_CACHEABLE;
    MPU_InitStruct.IsBufferable     = MPU_ACCESS_NOT_BUFFERABLE;
    MPU_InitStruct.IsShareable      = MPU_ACCESS_NOT_SHAREABLE;
    HAL_MPU_ConfigRegion(&MPU_InitStruct);

    /** Initializes and configures the Region and the memory to be protected
     */
    MPU_InitStruct.Number           = MPU_REGION_NUMBER1;
    MPU_InitStruct.BaseAddress      = 0x70000000;
    MPU_InitStruct.Size             = MPU_REGION_SIZE_32MB;
    MPU_InitStruct.SubRegionDisable = 0x0;
    MPU_InitStruct.AccessPermission = MPU_REGION_FULL_ACCESS;
    MPU_InitStruct.DisableExec      = MPU_INSTRUCTION_ACCESS_ENABLE;
    MPU_InitStruct.TypeExtField     = MPU_TEX_LEVEL1;
    MPU_InitStruct.IsCacheable      = MPU_ACCESS_CACHEABLE;
    MPU_InitStruct.IsBufferable     = MPU_ACCESS_NOT_BUFFERABLE;
    MPU_InitStruct.IsShareable      = MPU_ACCESS_NOT_SHAREABLE;
    HAL_MPU_ConfigRegion(&MPU_InitStruct);

    /** Initializes and configures the Region and the memory to be protected
     */
    MPU_InitStruct.Number           = MPU_REGION_NUMBER2;
    MPU_InitStruct.BaseAddress      = 0x24000000;
    MPU_InitStruct.Size             = MPU_REGION_SIZE_512KB;
    MPU_InitStruct.SubRegionDisable = 0x0;
    MPU_InitStruct.AccessPermission = MPU_REGION_FULL_ACCESS;
    MPU_InitStruct.DisableExec      = MPU_INSTRUCTION_ACCESS_ENABLE;
    MPU_InitStruct.TypeExtField     = MPU_TEX_LEVEL1;
    MPU_InitStruct.IsCacheable      = MPU_ACCESS_CACHEABLE;
    MPU_InitStruct.IsBufferable     = MPU_ACCESS_BUFFERABLE;
    MPU_InitStruct.IsShareable      = MPU_ACCESS_NOT_SHAREABLE;
    HAL_MPU_ConfigRegion(&MPU_InitStruct);

    MPU_InitStruct.Number           = MPU_REGION_NUMBER3;
    MPU_InitStruct.BaseAddress      = 0x20000000;
    MPU_InitStruct.Size             = MPU_REGION_SIZE_128KB;
    MPU_InitStruct.SubRegionDisable = 0x0;
    MPU_InitStruct.AccessPermission = MPU_REGION_FULL_ACCESS;
    MPU_InitStruct.DisableExec      = MPU_INSTRUCTION_ACCESS_ENABLE;
    MPU_InitStruct.TypeExtField     = MPU_TEX_LEVEL0;
    MPU_InitStruct.IsCacheable      = MPU_ACCESS_NOT_CACHEABLE;
    MPU_InitStruct.IsBufferable     = MPU_ACCESS_NOT_BUFFERABLE;
    MPU_InitStruct.IsShareable      = MPU_ACCESS_NOT_SHAREABLE;
    HAL_MPU_ConfigRegion(&MPU_InitStruct);

    MPU_InitStruct.Number           = MPU_REGION_NUMBER4;
    MPU_InitStruct.BaseAddress      = 0x30000000;
    MPU_InitStruct.Size             = MPU_REGION_SIZE_256KB;
    MPU_InitStruct.SubRegionDisable = 0x0;
    MPU_InitStruct.AccessPermission = MPU_REGION_FULL_ACCESS;
    MPU_InitStruct.DisableExec      = MPU_INSTRUCTION_ACCESS_ENABLE;
    MPU_InitStruct.TypeExtField     = MPU_TEX_LEVEL0;
    MPU_InitStruct.IsCacheable      = MPU_ACCESS_NOT_CACHEABLE;
    MPU_InitStruct.IsBufferable     = MPU_ACCESS_NOT_BUFFERABLE;
    MPU_InitStruct.IsShareable      = MPU_ACCESS_NOT_SHAREABLE;
    HAL_MPU_ConfigRegion(&MPU_InitStruct);

    /* Enables the MPU */
    HAL_MPU_Enable(MPU_PRIVILEGED_DEFAULT);
}

void HAL_TIM_PeriodElapsedCallback(TIM_HandleTypeDef *htim) {
    if (htim->Instance == TIM7) {
        HAL_IncTick();
    }
}

void Error_Handler(void) {
    __disable_irq();
    while (1) {
    }
}

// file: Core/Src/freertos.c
/* USER CODE BEGIN Header */
/**
  ******************************************************************************
  * File Name          : freertos.c
  * Description        : Code for freertos applications
  ******************************************************************************
  * @attention
  *
  * Copyright (c) 2025 STMicroelectronics.
  * All rights reserved.
  *
  * This software is licensed under terms that can be found in the LICENSE file
  * in the root directory of this software component.
  * If no LICENSE file comes with this software, it is provided AS-IS.
  *
  ******************************************************************************
  */
/* USER CODE END Header */

#include "FreeRTOS.h"
#include "task.h"
#include "main.h"
#include "cmsis_os.h"

/* USER CODE BEGIN Includes */

#include "fatfs.h"
#include "memorymap.h"
#include "sdmmc.h"
#include "usart.h"
#include "gpio.h"
#include <stdio.h>
#include <string.h>
#include "tim.h"
#include "lvgl.h"
#include "lvgl/examples/porting/lv_port_disp.h"
#include "lvgl/examples/porting/lv_port_indev.h"
/* USER CODE END Includes */

osThreadId Initial_TaskHandle;
osThreadId TouchSence_TaskHandle;
osThreadId Camera_TaskHandle;

void MX_FREERTOS_Init(void); /* (MISRA C 2004 rule 8.1) */

/* Hook prototypes */
void vApplicationIdleHook(void);
void vApplicationTickHook(void);
void vApplicationStackOverflowHook(TaskHandle_t xTask, signed char *pcTaskName);
void vApplicationMallocFailedHook(void);

/* USER CODE BEGIN 1 */
/* Functions needed when configGENERATE_RUN_TIME_STATS is on */
__weak void configureTimerForRunTimeStats(void) {
    HAL_TIM_Base_Start_IT(&htim3);
}
extern volatile unsigned long ulHighFrequencyTimerTicks;
__weak unsigned long getRunTimeCounterValue(void) {
    return ulHighFrequencyTimerTicks;
}
/* USER CODE END 1 */

/* USER CODE BEGIN 2 */
__weak void vApplicationIdleHook(void) {
    /* vApplicationIdleHook() will only be called if configUSE_IDLE_HOOK is set
     to 1 in FreeRTOSConfig.h. It will be called on each iteration of the idle
     task. It is essential that code added to this hook function never attempts
     to block in any way (for example, call xQueueReceive() with a block time
     specified, or call vTaskDelay()). If the application makes use of the
     vTaskDelete() API function (as this demo application does) then it is also
     important that vApplicationIdleHook() is permitted to return to its calling
     function, because it is the responsibility of the idle task to clean up
     memory allocated by the kernel to any task that has since been deleted. */
}
/* USER CODE END 2 */

/* USER CODE BEGIN 3 */
__weak void vApplicationTickHook( void )
{
   /* This function will be called by each tick interrupt if
   configUSE_TICK_HOOK is set to 1 in FreeRTOSConfig.h. User code can be
   added here, but the tick hook is called from an interrupt context, so
   code must not attempt to block, and only the interrupt safe FreeRTOS API
   functions can be used (those that end in FromISR()). */
    lv_tick_inc(1);
}
/* USER CODE END 3 */

/* USER CODE BEGIN 4 */
__weak void vApplicationStackOverflowHook(TaskHandle_t xTask, signed char *pcTaskName)
{
   /* Run time stack overflow checking is performed if
   configCHECK_FOR_STACK_OVERFLOW is defined to 1 or 2. This hook function is
   called if a stack overflow is detected. */
}
/* USER CODE END 4 */

/* USER CODE BEGIN 5 */
__weak void vApplicationMallocFailedHook(void)
{
   /* vApplicationMallocFailedHook() will only be called if
   configUSE_MALLOC_FAILED_HOOK is set to 1 in FreeRTOSConfig.h. It is a hook
   function that will get called if a call to pvPortMalloc() fails.
   pvPortMalloc() is called internally by the kernel whenever a task, queue,
   timer or semaphore is created. It is also called by various parts of the
   demo application. If heap_1.c or heap_2.c are used, then the size of the
   heap available to pvPortMalloc() is defined by configTOTAL_HEAP_SIZE in
   FreeRTOSConfig.h, and the xPortGetFreeHeapSize() API function can be used
   to query the size of free heap space that remains (although it does not
   provide information on how the remaining heap might be fragmented). */
}
/* USER CODE END 5 */

void MX_FREERTOS_Init(void) {

  /* USER CODE BEGIN RTOS_SEMAPHORES */
    /* add semaphores, ... */
    sema_flash_screen_routine_start = xSemaphoreCreateBinary();
    sema_camera_routine_start = xSemaphoreCreateBinary();
    sema_swap_buffer_handle = xSemaphoreCreateBinary();
  /* USER CODE END RTOS_SEMAPHORES */

  /* Create the thread(s) */
  /* definition and creation of Initial_Task */
  osThreadDef(Initial_Task, initial_task_routine, osPriorityAboveNormal, 0, 2048);
  Initial_TaskHandle = osThreadCreate(osThread(Initial_Task), NULL);

  /* definition and creation of TouchSence_Task */
  osThreadDef(TouchSence_Task, touch_sence_routine, osPriorityNormal, 0, 2048);
  TouchSence_TaskHandle = osThreadCreate(osThread(TouchSence_Task), NULL);

  /* definition and creation of Camera_Task */
  osThreadDef(Camera_Task, camera_task_routine, osPriorityNormal, 0, 8192);
  Camera_TaskHandle = osThreadCreate(osThread(Camera_Task), NULL);

  /* USER CODE BEGIN RTOS_THREADS */
    /* add threads, ... */
    vQueueAddToRegistry((QueueHandle_t) sema_flash_screen_routine_start, "sema_flash_screen_routine_start");
    vQueueAddToRegistry((QueueHandle_t) sema_camera_routine_start, "sema_camera_routine_start");
    vQueueAddToRegistry((QueueHandle_t) sema_swap_buffer_handle, "sema_swap_buffer_handle");
  /* USER CODE END RTOS_THREADS */

}

__weak void initial_task_routine(void const * argument)
{
    for (;;) {
        osDelay(1);
    }
}

__weak void touch_sence_routine(void const * argument)
{
  for(;;)
  {
    osDelay(1);
  }
}

__weak void camera_task_routine(void const * argument)
{
    for (;;) {
        osDelay(1);
    }
}
